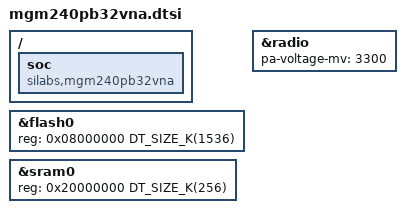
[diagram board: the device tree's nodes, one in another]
/*
 * Copyright (c) 2023 Fr. Sauter AG
 * Copyright (c) 2025 Silicon Laboratories Inc.
 *
 * SPDX-License-Identifier: Apache-2.0
 */

#include <mem.h>
#include <silabs/xg24/efr32mg24.dtsi>

/ {
	soc {
		compatible = "silabs,mgm240pb32vna", "silabs,efr32mg24", "silabs,xg24",
			     "silabs,efr32", "simple-bus";
	};
};

&flash0 {
	reg = <0x08000000 DT_SIZE_K(1536)>;
};

&radio {
	pa-voltage-mv = <3300>;
};

&sram0 {
	reg = <0x20000000 DT_SIZE_K(256)>;
};
